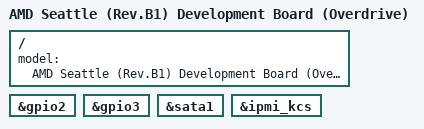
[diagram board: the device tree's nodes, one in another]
// SPDX-License-Identifier: GPL-2.0
/*
 * DTS file for AMD Seattle Overdrive Development Board
 * Note: For Seattle Rev.B1
 *
 * Copyright (C) 2015 Advanced Micro Devices, Inc.
 */

/dts-v1/;

/include/ "amd-overdrive-rev-b0.dts"

/ {
	model = "AMD Seattle (Rev.B1) Development Board (Overdrive)";
};

&gpio2 {
	status = "okay";
};

&gpio3 {
	status = "okay";
};

&sata1 {
	status = "okay";
};

&ipmi_kcs {
	status = "okay";
};

